# ATxmega256A3B device description
Architecture: AVR8_XMEGA; Family: AVR XMEGA
Registers are 8-bit, access not given, no defined reset value unless marked. A register's access mark holds for its fields unless they carry their own. Offsets are from the block's base; [hi:lo] are bit positions; {n}, {i} and the like mark numbered series; 'fields as' and 'values as' point back to an identical list.

## SLEEP — Sleep Controller
Instances: SLEEP 0x0048
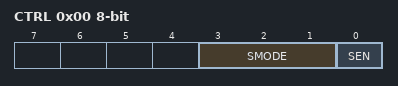
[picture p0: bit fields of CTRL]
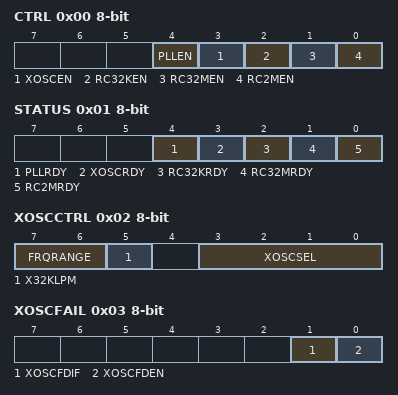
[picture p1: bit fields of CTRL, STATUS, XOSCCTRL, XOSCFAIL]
0x00 CTRL — Control Register
  [3:1] SMODE — Sleep Mode
    0=IDLE (Idle mode); 2=PDOWN (Power-down Mode); 3=PSAVE (Power-save Mode); 6=STDBY (Standby Mode); 7=ESTDBY (Extended Standby Mode)
  [0] SEN — Sleep Enable

## OSC — Oscillator
Instances: OSC 0x0050
0x00 CTRL — Control Register
  [4] PLLEN — PLL Enable
  [3] XOSCEN — External Oscillator Enable
  [2] RC32KEN — Internal 32kHz RC Oscillator Enable
  [1] RC32MEN — Internal 32MHz RC Oscillator Enable
  [0] RC2MEN — Internal 2MHz RC Oscillator Enable
0x01 STATUS
  [4] PLLRDY — PLL Ready
  [3] XOSCRDY — External Oscillator Ready
  [2] RC32KRDY — Internal 32kHz RC Oscillator Ready
  [1] RC32MRDY — Internal 32MHz RC Oscillator Ready
  [0] RC2MRDY — Internal 2MHz RC Oscillator Ready
0x02 XOSCCTRL — External Oscillator Control Register
  [7:6] FRQRANGE — Frequency Range
    0=04TO2 (0.4 - 2 MHz); 1=2TO9 (2 - 9 MHz); 2=9TO12 (9 - 12 MHz); 3=12TO16 (12 - 16 MHz)
  [5] X32KLPM — 32kHz XTAL OSC Low-power Mode
  [3:0] XOSCSEL — External Oscillator Selection and Startup Time
    0=EXTCLK (External Clock - 6 CLK); 2=32kHz TOSC - 32K CLK; 3=XTAL_256CLK (0.4-16MHz XTAL - 256 CLK); 7=XTAL_1KCLK (0.4-16MHz XTAL - 1K CLK); 11=XTAL_16KCLK (0.4-16MHz XTAL - 16K CLK)
0x03 XOSCFAIL — External Oscillator Failure Detection Register
  [1] XOSCFDIF — Failure Detection Interrupt Flag
  [0] XOSCFDEN — Failure Detection Enable
0x04 RC32KCAL — 32kHz Internal Oscillator Calibration Register
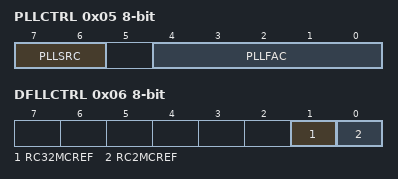
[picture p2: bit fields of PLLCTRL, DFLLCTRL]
0x05 PLLCTRL — PLL Control REgister
  [7:6] PLLSRC — Clock Source
    0=RC2M (Internal 2MHz RC Oscillator); 2=RC32M (Internal 32MHz RC Oscillator); 3=XOSC (External Oscillator)
  [4:0] PLLFAC — Multiplication Factor
0x06 DFLLCTRL — DFLL Control Register
  [1] RC32MCREF — 32MHz Calibration Reference
  [0] RC2MCREF — 2MHz Calibration Reference

## DFLL
Instances: DFLLRC32M 0x0060, DFLLRC2M 0x0068
0x00 CTRL — Control Register
  [0] ENABLE — DFLL Enable
0x02 CALA — Calibration Register A
  [6:0] CALL — DFLL Calibration bits [6:0]
0x03 CALB — Calibration Register B
  [5:0] CALH — DFLL Calibration bits [12:7]
{0x4+i} COMP{i} (i=0..2) — Oscillator Compare Register {i}

## RST — Reset
Instances: RST 0x0078
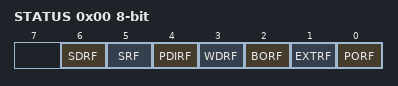
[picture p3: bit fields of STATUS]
0x00 STATUS
  [6] SDRF — Spike Detection Reset Flag
  [5] SRF — Software Reset Flag
  [4] PDIRF — Programming and Debug Interface Interface Reset Flag
  [3] WDRF — Watchdog Reset Flag
  [2] BORF — Brown-out Reset Flag
  [1] EXTRF — External Reset Flag
  [0] PORF — Power-on Reset Flag
0x01 CTRL — Control Register
  [0] SWRST — Software Reset

## WDT — Watch-Dog Timer
Instances: WDT 0x0080
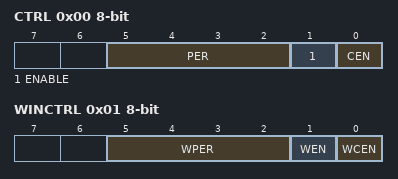
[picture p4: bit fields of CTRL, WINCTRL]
0x00 CTRL — Control
  [5:2] PER — Period
    0=8CLK (8 cycles (8ms @ 3.3V)); 1=16CLK (16 cycles (16ms @ 3.3V)); 2=32CLK (32 cycles (32ms @ 3.3V)); 3=64CLK (64 cycles (64ms @ 3.3V)); 4=128CLK (128 cycles (0.128s @ 3.3V)); 5=256CLK (256 cycles (0.256s @ 3.3V)); 6=512CLK (512 cycles (0.512s @ 3.3V)); 7=1KCLK (1K cycles (1s @ 3.3V)); 8=2KCLK (2K cycles (2s @ 3.3V)); 9=4KCLK (4K cycles (4s @ 3.3V)); 10=8KCLK (8K cycles (8s @ 3.3V))
  [1] ENABLE
  [0] CEN — Change Enable
0x01 WINCTRL — Windowed Mode Control
  [5:2] WPER — Windowed Mode Period
    values as CTRL.PER
  [1] WEN — Windowed Mode Enable
  [0] WCEN — Windowed Mode Change Enable
0x02 STATUS
  [0] SYNCBUSY — Syncronization busy

## MCU — MCU Control
Instances: MCU 0x0090
{0x0+i} DEVID{i} (i=0..2) — Device ID byte {i}
0x03 REVID — Revision ID
0x04 JTAGUID — JTAG User ID
0x06 MCUCR — MCU Control
  [0] JTAGD — JTAG Disable
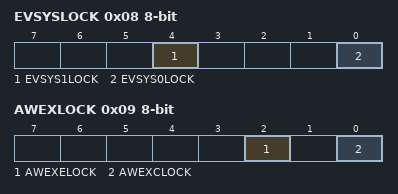
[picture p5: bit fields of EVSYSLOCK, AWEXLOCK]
0x08 EVSYSLOCK — Event System Lock
  [4] EVSYS1LOCK — Event Channel 4-7 Lock
  [0] EVSYS0LOCK — Event Channel 0-3 Lock
0x09 AWEXLOCK
  [2] AWEXELOCK — AWeX on T/C E0 Lock
  [0] AWEXCLOCK — AWeX on T/C C0 Lock
